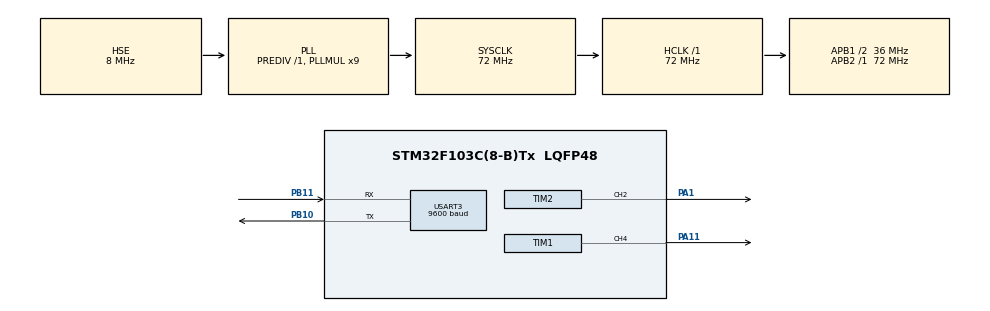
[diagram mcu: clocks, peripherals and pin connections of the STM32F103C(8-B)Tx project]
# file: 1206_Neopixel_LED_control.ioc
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Dma.Request0=TIM2_CH2/CH4
Dma.TIM2_CH2/CH4.0.Direction=DMA_MEMORY_TO_PERIPH
Dma.TIM2_CH2/CH4.0.Instance=DMA1_Channel7
Dma.TIM2_CH2/CH4.0.MemDataAlignment=DMA_MDATAALIGN_HALFWORD
Dma.TIM2_CH2/CH4.0.MemInc=DMA_MINC_ENABLE
Dma.TIM2_CH2/CH4.0.Mode=DMA_NORMAL
Dma.TIM2_CH2/CH4.0.PeriphDataAlignment=DMA_PDATAALIGN_HALFWORD
Dma.TIM2_CH2/CH4.0.PeriphInc=DMA_PINC_DISABLE
Dma.TIM2_CH2/CH4.0.Priority=DMA_PRIORITY_LOW
Mcu.Family=STM32F1
Mcu.Name=STM32F103C(8-B)Tx
Mcu.Package=LQFP48
NVIC.DMA1_Channel7_IRQn=true\:0\:0\:false\:false\:true\:false\:true\:true
NVIC.PriorityGroup=NVIC_PRIORITYGROUP_4
NVIC.USART3_IRQn=true\:0\:0\:false\:false\:true\:true\:true\:true
PA1.Signal=S_TIM2_CH2
PA11.Signal=S_TIM1_CH4
PA13.Mode=Serial_Wire
PA13.Signal=SYS_JTMS-SWDIO
PA14.Mode=Serial_Wire
PA14.Signal=SYS_JTCK-SWCLK
PB10.Mode=Asynchronous
PB10.Signal=USART3_TX
PB11.Mode=Asynchronous
PB11.Signal=USART3_RX
PD0-OSC_IN.Mode=HSE-External-Oscillator
PD0-OSC_IN.Signal=RCC_OSC_IN
PD1-OSC_OUT.Mode=HSE-External-Oscillator
PD1-OSC_OUT.Signal=RCC_OSC_OUT
ProjectManager.HeapSize=0x200
ProjectManager.StackSize=0x400
ProjectManager.TargetToolchain=MDK-ARM V5.32
RCC.AHBFreq_Value=72000000
RCC.APB1CLKDivider=RCC_HCLK_DIV2
RCC.APB1Freq_Value=36000000
RCC.APB1TimFreq_Value=72000000
RCC.APB2Freq_Value=72000000
RCC.APB2TimFreq_Value=72000000
RCC.HCLKFreq_Value=72000000
RCC.PLLMUL=RCC_PLL_MUL9
RCC.PLLSourceVirtual=RCC_PLLSOURCE_HSE
RCC.SYSCLKFreq_VALUE=72000000
RCC.SYSCLKSource=RCC_SYSCLKSOURCE_PLLCLK
RCC.USBFreq_Value=72000000
SH.S_TIM1_CH4.0=TIM1_CH4,PWM Generation4 CH4
SH.S_TIM2_CH2.0=TIM2_CH2,PWM Generation2 CH2
TIM1.Channel-PWM\ Generation4\ CH4=TIM_CHANNEL_4
TIM1.Period=71
TIM2.Channel-PWM\ Generation2\ CH2=TIM_CHANNEL_2
TIM2.Period=89
USART3.BaudRate=9600
USART3.VirtualMode=VM_ASYNC
VP_TIM1_VS_ClockSourceINT.Mode=Internal
VP_TIM2_VS_ClockSourceINT.Mode=Internal
board=custom

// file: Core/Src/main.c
/* USER CODE BEGIN Header */
/**
  ******************************************************************************
  * @file           : main.c
  * @brief          : Main program body
  ******************************************************************************
  * @attention
  *
  * Copyright (c) 2024 STMicroelectronics.
  * All rights reserved.
  *
  * This software is licensed under terms that can be found in the LICENSE file
  * in the root directory of this software component.
  * If no LICENSE file comes with this software, it is provided AS-IS.
  *
  ******************************************************************************
  */
/* USER CODE END Header */
#include "main.h"

/* USER CODE BEGIN Includes */
#include "LED.h"
#include "UART.h"
/* USER CODE END Includes */

TIM_HandleTypeDef htim1;
TIM_HandleTypeDef htim2;
DMA_HandleTypeDef hdma_tim2_ch2_ch4;

UART_HandleTypeDef huart3;

void SystemClock_Config(void);
static void MX_GPIO_Init(void);
static void MX_DMA_Init(void);
static void MX_TIM2_Init(void);
static void MX_TIM1_Init(void);
static void MX_USART3_UART_Init(void);

/* USER CODE BEGIN 0 */

uint8_t n,r,g,b;

uint8_t bt_arr[20];
/* USER CODE END 0 */

int main(void)
{

  /* MCU Configuration--------------------------------------------------------*/

  /* Reset of all peripherals, Initializes the Flash interface and the Systick. */
  HAL_Init();

  /* Configure the system clock */
  SystemClock_Config();

  /* Initialize all configured peripherals */
  MX_GPIO_Init();
  MX_DMA_Init();
  MX_TIM2_Init();
  MX_TIM1_Init();
  MX_USART3_UART_Init();
  /* USER CODE BEGIN 2 */

	// led data input
	led_off();

		HAL_UART_Receive_IT(&huart3, &bt_uart_one, 1);

  /* USER CODE END 2 */

  /* Infinite loop */
  while (1)
  {

    /* USER CODE BEGIN 3 */

		bt_color_change();

		search_color(r,g,b,n);

  }
  /* USER CODE END 3 */
}

void SystemClock_Config(void)
{
  RCC_OscInitTypeDef RCC_OscInitStruct = {0};
  RCC_ClkInitTypeDef RCC_ClkInitStruct = {0};

  /** Initializes the RCC Oscillators according to the specified parameters
  * in the RCC_OscInitTypeDef structure.
  */
  RCC_OscInitStruct.OscillatorType = RCC_OSCILLATORTYPE_HSE;
  RCC_OscInitStruct.HSEState = RCC_HSE_ON;
  RCC_OscInitStruct.HSEPredivValue = RCC_HSE_PREDIV_DIV1;
  RCC_OscInitStruct.HSIState = RCC_HSI_ON;
  RCC_OscInitStruct.PLL.PLLState = RCC_PLL_ON;
  RCC_OscInitStruct.PLL.PLLSource = RCC_PLLSOURCE_HSE;
  RCC_OscInitStruct.PLL.PLLMUL = RCC_PLL_MUL9;
  if (HAL_RCC_OscConfig(&RCC_OscInitStruct) != HAL_OK)
  {
    Error_Handler();
  }

  /** Initializes the CPU, AHB and APB buses clocks
  */
  RCC_ClkInitStruct.ClockType = RCC_CLOCKTYPE_HCLK|RCC_CLOCKTYPE_SYSCLK
                              |RCC_CLOCKTYPE_PCLK1|RCC_CLOCKTYPE_PCLK2;
  RCC_ClkInitStruct.SYSCLKSource = RCC_SYSCLKSOURCE_PLLCLK;
  RCC_ClkInitStruct.AHBCLKDivider = RCC_SYSCLK_DIV1;
  RCC_ClkInitStruct.APB1CLKDivider = RCC_HCLK_DIV2;
  RCC_ClkInitStruct.APB2CLKDivider = RCC_HCLK_DIV1;

  if (HAL_RCC_ClockConfig(&RCC_ClkInitStruct, FLASH_LATENCY_2) != HAL_OK)
  {
    Error_Handler();
  }
}

static void MX_TIM1_Init(void)
{

  TIM_ClockConfigTypeDef sClockSourceConfig = {0};
  TIM_MasterConfigTypeDef sMasterConfig = {0};
  TIM_OC_InitTypeDef sConfigOC = {0};
  TIM_BreakDeadTimeConfigTypeDef sBreakDeadTimeConfig = {0};

  htim1.Instance = TIM1;
  htim1.Init.Prescaler = 0;
  htim1.Init.CounterMode = TIM_COUNTERMODE_UP;
  htim1.Init.Period = 71;
  htim1.Init.ClockDivision = TIM_CLOCKDIVISION_DIV1;
  htim1.Init.RepetitionCounter = 0;
  htim1.Init.AutoReloadPreload = TIM_AUTORELOAD_PRELOAD_DISABLE;
  if (HAL_TIM_Base_Init(&htim1) != HAL_OK)
  {
    Error_Handler();
  }
  sClockSourceConfig.ClockSource = TIM_CLOCKSOURCE_INTERNAL;
  if (HAL_TIM_ConfigClockSource(&htim1, &sClockSourceConfig) != HAL_OK)
  {
    Error_Handler();
  }
  if (HAL_TIM_PWM_Init(&htim1) != HAL_OK)
  {
    Error_Handler();
  }
  sMasterConfig.MasterOutputTrigger = TIM_TRGO_RESET;
  sMasterConfig.MasterSlaveMode = TIM_MASTERSLAVEMODE_DISABLE;
  if (HAL_TIMEx_MasterConfigSynchronization(&htim1, &sMasterConfig) != HAL_OK)
  {
    Error_Handler();
  }
  sConfigOC.OCMode = TIM_OCMODE_PWM1;
  sConfigOC.Pulse = 0;
  sConfigOC.OCPolarity = TIM_OCPOLARITY_HIGH;
  sConfigOC.OCFastMode = TIM_OCFAST_DISABLE;
  sConfigOC.OCIdleState = TIM_OCIDLESTATE_RESET;
  sConfigOC.OCNIdleState = TIM_OCNIDLESTATE_RESET;
  if (HAL_TIM_PWM_ConfigChannel(&htim1, &sConfigOC, TIM_CHANNEL_4) != HAL_OK)
  {
    Error_Handler();
  }
  sBreakDeadTimeConfig.OffStateRunMode = TIM_OSSR_DISABLE;
  sBreakDeadTimeConfig.OffStateIDLEMode = TIM_OSSI_DISABLE;
  sBreakDeadTimeConfig.LockLevel = TIM_LOCKLEVEL_OFF;
  sBreakDeadTimeConfig.DeadTime = 0;
  sBreakDeadTimeConfig.BreakState = TIM_BREAK_DISABLE;
  sBreakDeadTimeConfig.BreakPolarity = TIM_BREAKPOLARITY_HIGH;
  sBreakDeadTimeConfig.AutomaticOutput = TIM_AUTOMATICOUTPUT_DISABLE;
  if (HAL_TIMEx_ConfigBreakDeadTime(&htim1, &sBreakDeadTimeConfig) != HAL_OK)
  {
    Error_Handler();
  }
  HAL_TIM_MspPostInit(&htim1);

}

static void MX_TIM2_Init(void)
{

  TIM_ClockConfigTypeDef sClockSourceConfig = {0};
  TIM_MasterConfigTypeDef sMasterConfig = {0};
  TIM_OC_InitTypeDef sConfigOC = {0};

  htim2.Instance = TIM2;
  htim2.Init.Prescaler = 0;
  htim2.Init.CounterMode = TIM_COUNTERMODE_UP;
  htim2.Init.Period = 89;
  htim2.Init.ClockDivision = TIM_CLOCKDIVISION_DIV1;
  htim2.Init.AutoReloadPreload = TIM_AUTORELOAD_PRELOAD_DISABLE;
  if (HAL_TIM_Base_Init(&htim2) != HAL_OK)
  {
    Error_Handler();
  }
  sClockSourceConfig.ClockSource = TIM_CLOCKSOURCE_INTERNAL;
  if (HAL_TIM_ConfigClockSource(&htim2, &sClockSourceConfig) != HAL_OK)
  {
    Error_Handler();
  }
  if (HAL_TIM_PWM_Init(&htim2) != HAL_OK)
  {
    Error_Handler();
  }
  sMasterConfig.MasterOutputTrigger = TIM_TRGO_RESET;
  sMasterConfig.MasterSlaveMode = TIM_MASTERSLAVEMODE_DISABLE;
  if (HAL_TIMEx_MasterConfigSynchronization(&htim2, &sMasterConfig) != HAL_OK)
  {
    Error_Handler();
  }
  sConfigOC.OCMode = TIM_OCMODE_PWM1;
  sConfigOC.Pulse = 0;
  sConfigOC.OCPolarity = TIM_OCPOLARITY_HIGH;
  sConfigOC.OCFastMode = TIM_OCFAST_DISABLE;
  if (HAL_TIM_PWM_ConfigChannel(&htim2, &sConfigOC, TIM_CHANNEL_2) != HAL_OK)
  {
    Error_Handler();
  }
  HAL_TIM_MspPostInit(&htim2);

}

static void MX_USART3_UART_Init(void)
{

  huart3.Instance = USART3;
  huart3.Init.BaudRate = 9600;
  huart3.Init.WordLength = UART_WORDLENGTH_8B;
  huart3.Init.StopBits = UART_STOPBITS_1;
  huart3.Init.Parity = UART_PARITY_NONE;
  huart3.Init.Mode = UART_MODE_TX_RX;
  huart3.Init.HwFlowCtl = UART_HWCONTROL_NONE;
  huart3.Init.OverSampling = UART_OVERSAMPLING_16;
  if (HAL_UART_Init(&huart3) != HAL_OK)
  {
    Error_Handler();
  }

}

static void MX_DMA_Init(void)
{

  /* DMA controller clock enable */
  __HAL_RCC_DMA1_CLK_ENABLE();

  /* DMA interrupt init */
  /* DMA1_Channel7_IRQn interrupt configuration */
  HAL_NVIC_SetPriority(DMA1_Channel7_IRQn, 0, 0);
  HAL_NVIC_EnableIRQ(DMA1_Channel7_IRQn);

}

static void MX_GPIO_Init(void)
{

  /* GPIO Ports Clock Enable */
  __HAL_RCC_GPIOD_CLK_ENABLE();
  __HAL_RCC_GPIOA_CLK_ENABLE();
  __HAL_RCC_GPIOB_CLK_ENABLE();

}

void Error_Handler(void)
{
  __disable_irq();
  while (1)
  {
  }
}
